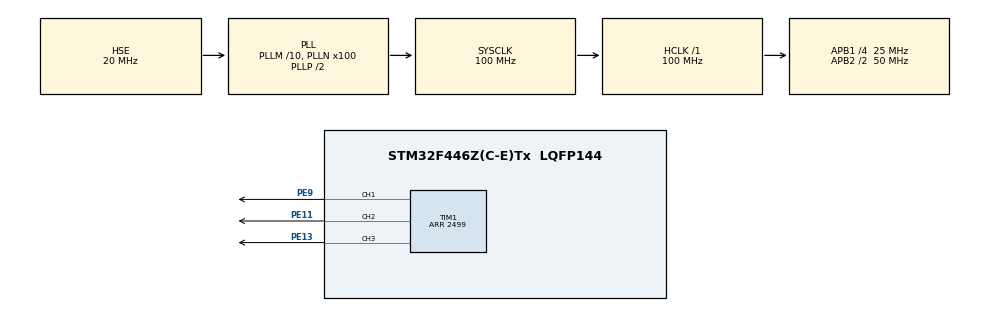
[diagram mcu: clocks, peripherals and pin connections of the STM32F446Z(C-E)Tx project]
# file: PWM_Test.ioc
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Mcu.Family=STM32F4
Mcu.Name=STM32F446Z(C-E)Tx
Mcu.Package=LQFP144
NVIC.PriorityGroup=NVIC_PRIORITYGROUP_4
NVIC.TIM1_CC_IRQn=true\:0\:0\:false\:false\:true\:true\:true\:true
PE11.Signal=S_TIM1_CH2
PE13.Signal=S_TIM1_CH3
PE9.Signal=S_TIM1_CH1
PH0-OSC_IN.Mode=HSE-External-Oscillator
PH0-OSC_IN.Signal=RCC_OSC_IN
PH1-OSC_OUT.Mode=HSE-External-Oscillator
PH1-OSC_OUT.Signal=RCC_OSC_OUT
ProjectManager.HeapSize=0x200
ProjectManager.StackSize=0x400
ProjectManager.TargetToolchain=STM32CubeIDE
RCC.AHBFreq_Value=100000000
RCC.APB1CLKDivider=RCC_HCLK_DIV4
RCC.APB1Freq_Value=25000000
RCC.APB1TimFreq_Value=50000000
RCC.APB2CLKDivider=RCC_HCLK_DIV2
RCC.APB2Freq_Value=50000000
RCC.APB2TimFreq_Value=100000000
RCC.CortexFreq_Value=100000000
RCC.HCLKFreq_Value=100000000
RCC.HSE_VALUE=20000000
RCC.PLLM=10
RCC.PLLN=100
RCC.PLLSourceVirtual=RCC_PLLSOURCE_HSE
RCC.SYSCLKFreq_VALUE=100000000
RCC.SYSCLKSource=RCC_SYSCLKSOURCE_PLLCLK
RCC.USBFreq_Value=100000000
RCC.VCOOutputFreq_Value=200000000
SH.S_TIM1_CH1.0=TIM1_CH1,PWM Generation1 CH1
SH.S_TIM1_CH2.0=TIM1_CH2,PWM Generation2 CH2
SH.S_TIM1_CH3.0=TIM1_CH3,PWM Generation3 CH3
TIM1.AutoReloadPreload=TIM_AUTORELOAD_PRELOAD_ENABLE
TIM1.Channel-PWM\ Generation1\ CH1=TIM_CHANNEL_1
TIM1.Channel-PWM\ Generation2\ CH2=TIM_CHANNEL_2
TIM1.Channel-PWM\ Generation3\ CH3=TIM_CHANNEL_3
TIM1.CounterMode=TIM_COUNTERMODE_CENTERALIGNED3
TIM1.OCMode_PWM-PWM\ Generation2\ CH2=TIM_OCMODE_PWM1
TIM1.Period=2499
VP_TIM1_VS_ClockSourceINT.Mode=Internal
board=custom

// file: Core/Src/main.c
/* USER CODE BEGIN Header */
/**
  ******************************************************************************
  * @file           : main.c
  * @brief          : Main program body
  ******************************************************************************
  * @attention
  *
  * Copyright (c) 2026 STMicroelectronics.
  * All rights reserved.
  *
  * This software is licensed under terms that can be found in the LICENSE file
  * in the root directory of this software component.
  * If no LICENSE file comes with this software, it is provided AS-IS.
  *
  ******************************************************************************
  */
/* USER CODE END Header */
#include "main.h"
#include <math.h>

/* USER CODE BEGIN PD */

#define PI 3.14159265358979323846f
#define DEG2RAD(deg) ((deg) * (PI / 180.0f))

typedef struct {
	float theta;
	float freq; // Freq in Hz
	float dt; // PWM Freq
	float w; // Freq in Rad/s

	float Va;
	float Vb;
	float Vc;

	uint16_t PWM_A;
	uint16_t PWM_B;
	uint16_t PWM_C;
} Freq_Param;

Freq_Param Freq = {
		.dt = 1/(20e3),
		.freq = 2, // 50 Hz adjustable
		.theta = 0.0, // 0 Rad initial
		.w = 0.0,
		.PWM_A = 0,
		.PWM_B = 0,
		.PWM_C = 0
};
/* USER CODE END PD */

TIM_HandleTypeDef htim1;

void SystemClock_Config(void);
static void MX_GPIO_Init(void);
static void MX_TIM1_Init(void);

/* USER CODE BEGIN 0 */
/* PWM Interrupt Callback */
void HAL_TIM_PeriodElapsedCallback(TIM_HandleTypeDef *htim) {
	if (htim->Instance == TIM1)
	    {
		  Freq.w = 2*PI*Freq.freq;
		  Freq.theta += Freq.w * Freq.dt/2;

		  TIM1->CCR1 = Freq.PWM_A;
		  TIM1->CCR2 = Freq.PWM_B;
		  TIM1->CCR3 = Freq.PWM_C;
	        // Your code to run on each period elapsed event (overflow/underflow)
	        // In Mode 3, this happens twice per PWM period (at the top and bottom of the count)
	        // You might use a state variable or the repetition counter (if available)
	        // to handle events that should only happen once per cycle.
	    }
}
/* USER CODE END 0 */

int main(void)
{

  /* MCU Configuration--------------------------------------------------------*/

  /* Reset of all peripherals, Initializes the Flash interface and the Systick. */
  HAL_Init();

  /* Configure the system clock */
  SystemClock_Config();

  /* Initialize all configured peripherals */
  MX_GPIO_Init();
  MX_TIM1_Init();
  /* USER CODE BEGIN 2 */
  HAL_TIM_PWM_Start(&htim1, TIM_CHANNEL_1);
  HAL_TIM_PWM_Start(&htim1, TIM_CHANNEL_2);
  HAL_TIM_PWM_Start(&htim1, TIM_CHANNEL_3);
  /* USER CODE END 2 */

  /* Infinite loop */
  while (1)
  {

  }
}

void SystemClock_Config(void)
{
  RCC_OscInitTypeDef RCC_OscInitStruct = {0};
  RCC_ClkInitTypeDef RCC_ClkInitStruct = {0};

  /** Configure the main internal regulator output voltage
  */
  __HAL_RCC_PWR_CLK_ENABLE();
  __HAL_PWR_VOLTAGESCALING_CONFIG(PWR_REGULATOR_VOLTAGE_SCALE3);

  /** Initializes the RCC Oscillators according to the specified parameters
  * in the RCC_OscInitTypeDef structure.
  */
  RCC_OscInitStruct.OscillatorType = RCC_OSCILLATORTYPE_HSE;
  RCC_OscInitStruct.HSEState = RCC_HSE_ON;
  RCC_OscInitStruct.PLL.PLLState = RCC_PLL_ON;
  RCC_OscInitStruct.PLL.PLLSource = RCC_PLLSOURCE_HSE;
  RCC_OscInitStruct.PLL.PLLM = 10;
  RCC_OscInitStruct.PLL.PLLN = 100;
  RCC_OscInitStruct.PLL.PLLP = RCC_PLLP_DIV2;
  RCC_OscInitStruct.PLL.PLLQ = 2;
  RCC_OscInitStruct.PLL.PLLR = 2;
  if (HAL_RCC_OscConfig(&RCC_OscInitStruct) != HAL_OK)
  {
    Error_Handler();
  }

  /** Initializes the CPU, AHB and APB buses clocks
  */
  RCC_ClkInitStruct.ClockType = RCC_CLOCKTYPE_HCLK|RCC_CLOCKTYPE_SYSCLK
                              |RCC_CLOCKTYPE_PCLK1|RCC_CLOCKTYPE_PCLK2;
  RCC_ClkInitStruct.SYSCLKSource = RCC_SYSCLKSOURCE_PLLCLK;
  RCC_ClkInitStruct.AHBCLKDivider = RCC_SYSCLK_DIV1;
  RCC_ClkInitStruct.APB1CLKDivider = RCC_HCLK_DIV4;
  RCC_ClkInitStruct.APB2CLKDivider = RCC_HCLK_DIV2;

  if (HAL_RCC_ClockConfig(&RCC_ClkInitStruct, FLASH_LATENCY_3) != HAL_OK)
  {
    Error_Handler();
  }
}

static void MX_TIM1_Init(void)
{

  TIM_ClockConfigTypeDef sClockSourceConfig = {0};
  TIM_MasterConfigTypeDef sMasterConfig = {0};
  TIM_OC_InitTypeDef sConfigOC = {0};
  TIM_BreakDeadTimeConfigTypeDef sBreakDeadTimeConfig = {0};

  htim1.Instance = TIM1;
  htim1.Init.Prescaler = 0;
  htim1.Init.CounterMode = TIM_COUNTERMODE_CENTERALIGNED3;
  htim1.Init.Period = 2499;
  htim1.Init.ClockDivision = TIM_CLOCKDIVISION_DIV1;
  htim1.Init.RepetitionCounter = 0;
  htim1.Init.AutoReloadPreload = TIM_AUTORELOAD_PRELOAD_ENABLE;
  if (HAL_TIM_Base_Init(&htim1) != HAL_OK)
  {
    Error_Handler();
  }
  sClockSourceConfig.ClockSource = TIM_CLOCKSOURCE_INTERNAL;
  if (HAL_TIM_ConfigClockSource(&htim1, &sClockSourceConfig) != HAL_OK)
  {
    Error_Handler();
  }
  if (HAL_TIM_PWM_Init(&htim1) != HAL_OK)
  {
    Error_Handler();
  }
  sMasterConfig.MasterOutputTrigger = TIM_TRGO_RESET;
  sMasterConfig.MasterSlaveMode = TIM_MASTERSLAVEMODE_DISABLE;
  if (HAL_TIMEx_MasterConfigSynchronization(&htim1, &sMasterConfig) != HAL_OK)
  {
    Error_Handler();
  }
  sConfigOC.OCMode = TIM_OCMODE_PWM1;
  sConfigOC.Pulse = 500;
  sConfigOC.OCPolarity = TIM_OCPOLARITY_HIGH;
  sConfigOC.OCNPolarity = TIM_OCNPOLARITY_HIGH;
  sConfigOC.OCFastMode = TIM_OCFAST_DISABLE;
  sConfigOC.OCIdleState = TIM_OCIDLESTATE_RESET;
  sConfigOC.OCNIdleState = TIM_OCNIDLESTATE_RESET;
  if (HAL_TIM_PWM_ConfigChannel(&htim1, &sConfigOC, TIM_CHANNEL_1) != HAL_OK)
  {
    Error_Handler();
  }
  if (HAL_TIM_PWM_ConfigChannel(&htim1, &sConfigOC, TIM_CHANNEL_2) != HAL_OK)
  {
    Error_Handler();
  }
  if (HAL_TIM_PWM_ConfigChannel(&htim1, &sConfigOC, TIM_CHANNEL_3) != HAL_OK)
  {
    Error_Handler();
  }
  sBreakDeadTimeConfig.OffStateRunMode = TIM_OSSR_DISABLE;
  sBreakDeadTimeConfig.OffStateIDLEMode = TIM_OSSI_DISABLE;
  sBreakDeadTimeConfig.LockLevel = TIM_LOCKLEVEL_OFF;
  sBreakDeadTimeConfig.DeadTime = 0;
  sBreakDeadTimeConfig.BreakState = TIM_BREAK_DISABLE;
  sBreakDeadTimeConfig.BreakPolarity = TIM_BREAKPOLARITY_HIGH;
  sBreakDeadTimeConfig.AutomaticOutput = TIM_AUTOMATICOUTPUT_DISABLE;
  if (HAL_TIMEx_ConfigBreakDeadTime(&htim1, &sBreakDeadTimeConfig) != HAL_OK)
  {
    Error_Handler();
  }
  HAL_TIM_MspPostInit(&htim1);

}

static void MX_GPIO_Init(void)
{

  /* GPIO Ports Clock Enable */
  __HAL_RCC_GPIOH_CLK_ENABLE();
  __HAL_RCC_GPIOE_CLK_ENABLE();

}

void Error_Handler(void)
{
  __disable_irq();
  while (1)
  {
  }
}
